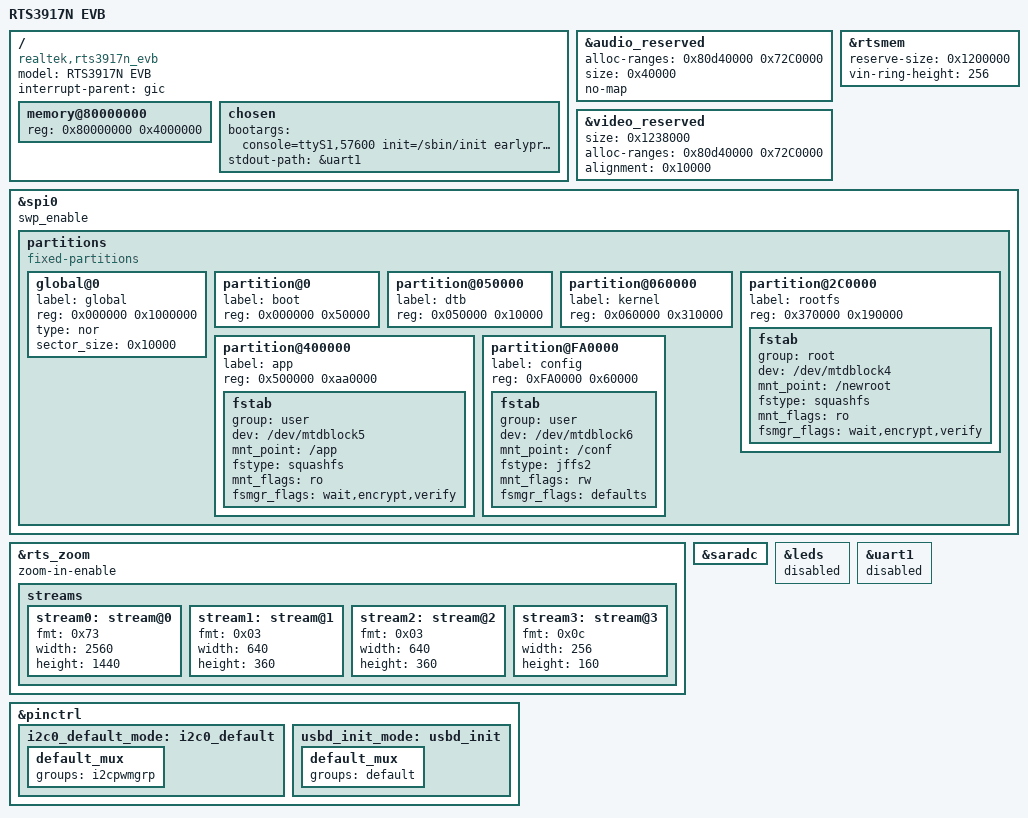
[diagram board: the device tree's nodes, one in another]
#include "rts3917n.dtsi"

/ {
	model = "RTS3917N EVB";
	compatible = "realtek,rts3917n_evb", "realtek,rts3917";

	#address-cells = <1>;
	#size-cells = <1>;
	interrupt-parent = <&gic>;

	memory@80000000 {
		device_type = "memory";
		reg = <0x80000000 0x4000000>;
	};

	chosen {
		bootargs = "console=ttyS1,57600 init=/sbin/init earlyprintk psci=enable root=/dev/mtdblock4 rootfstype=squashfs user_debug=31";
		stdout-path = &uart1;
	};
};

&audio_reserved {
	alloc-ranges = <0x80d40000 0x72C0000>;
	size = <0x40000>;
	no-map;
};

&video_reserved {
	//compatible = "shared-dma-pool";
	//reusable;
	size = <0x1238000>;
	alloc-ranges = <0x80d40000 0x72C0000>;
	alignment = <0x10000>;
};

&rtsmem {
	reserve-size = <0x1200000>;
	vin-ring-height = <256>;
};

&spi0 {
	status = "okay";
	swp_enable;
	partitions {
		compatible = "fixed-partitions";
		#address-cells = <1>;
		#size-cells = <1>;

		global@0 {
			label = "global";
			reg = <0x000000 0x1000000>; //flash size, 16M = 256 * 64k
			type = "nor";
			sector_size = <0x10000>;
		};

		partition@0 {
			label = "boot";
			reg = <0x000000 0x50000>; //(5*64K)4*64K for uboot, 1*64K for hconf
		};

		partition@050000 {
			label = "dtb";
			reg = <0x050000 0x10000>; //1*64K
		};

		partition@060000 {
			label = "kernel";
			reg = <0x060000 0x310000>; //38*64K
		};

		partition@2C0000 {
			label = "rootfs";
			reg = <0x370000 0x190000>; //20*64K
			fstab {
				group = "root";
				dev = "/dev/mtdblock4";
				mnt_point = "/newroot";
				fstype = "squashfs";
				mnt_flags = "ro";
				fsmgr_flags = "wait,encrypt,verify";
			};
		};

		partition@400000 {
			label = "app";
			reg = <0x500000 0xaa0000>; //186*64K
			fstab {
				group = "user";
				dev = "/dev/mtdblock5";
				mnt_point = "/app";
				fstype = "squashfs";
				mnt_flags = "ro";
				fsmgr_flags = "wait,encrypt,verify";
			};
		};

		partition@FA0000 {
			label = "config";
			reg = <0xFA0000 0x60000>; //6*64K
			fstab {
				group = "user";
				dev = "/dev/mtdblock6";
				mnt_point = "/conf";
				fstype = "jffs2";
				mnt_flags = "rw";
				fsmgr_flags = "defaults";
			};
		};
	};
};

&rts_zoom {
	status = "okay";
	zoom-in-enable;
	// clock-frequency = <160000000>;

	streams {
		stream0: stream@0 {
			fmt = <0x73>;
			width = <2560>;
			height = <1440>;
		};
		stream1: stream@1 {
			fmt = <0x03>;
			width = <640>;
			height = <360>;
		};
		stream2: stream@2 {
			fmt = <0x03>;
			width = <640>;
			height = <360>;
		};
		stream3: stream@3 {
			fmt = <0x0c>;
			width = <256>;
			height = <160>;
		};
	};
};

&saradc {
	status = "okay";
};

&pinctrl {
	i2c0_default_mode: i2c0_default {
		default_mux {
			groups = "i2cpwmgrp";
		};
	};

	usbd_init_mode: usbd_init {
		default_mux {
			groups = "default";
		};
	};
};

&leds {
	status = "disabled";
};

&uart1 {
	status = "disabled";
};
